# STM32F4_EXCERPT register map
STM32F4 GPIOA + USART1 excerpt (external anchor)
Registers are 32-bit, access not given, no defined reset value unless marked. A register's access mark holds for its fields unless they carry their own. Offsets are from the block's base; lines under a group give offsets from that group; [hi:lo] are bit positions; {n}, {i} and the like mark numbered series; 'fields as' and 'values as' point back to an identical list; <NAME> marks a mode.

## Memory map
0x40011000 USART1 — Universal synchronous asynchronous receiver transmitter
0x40020000 GPIOA — General-purpose I/Os

## GPIOA — General-purpose I/Os
Base 0x40020000
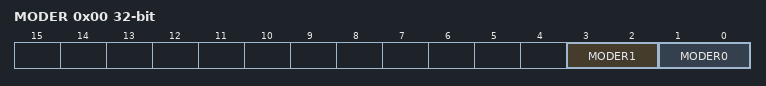
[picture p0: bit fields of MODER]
0x00 MODER — GPIO port mode register
  [3:2] MODER1 — Port x configuration bits (y = 1)
  [1:0] MODER0 — Port x configuration bits (y = 0)
0x14 ODR — GPIO port output data register
  [0] ODR0 — Port output data (y = 0)

## USART1 — Universal synchronous asynchronous receiver transmitter
Base 0x40011000
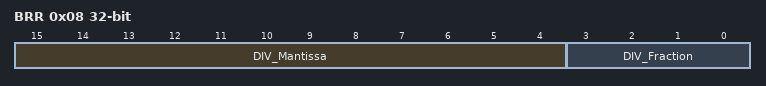
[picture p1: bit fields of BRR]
0x08 BRR — Baud rate register
  [15:4] DIV_Mantissa — mantissa of USARTDIV
  [3:0] DIV_Fraction — fraction of USARTDIV
